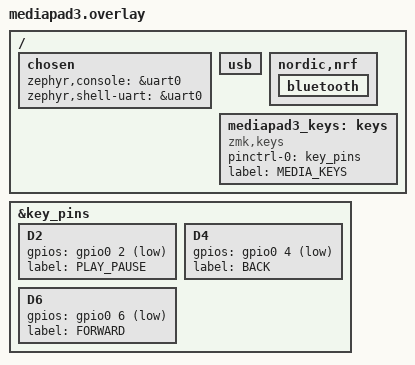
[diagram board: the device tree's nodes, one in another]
/ {
    chosen {
        zephyr,console = &uart0;
        zephyr,shell-uart = &uart0;
    };

    usb {
        status = "okay";
        #address-cells = <1>;
        #size-cells = <0>;
    };

    nordic,nrf {
        bluetooth {
            status = "okay";
        };
    };
};

/ {
    mediapad3_keys: keys {
        compatible = "zmk,keys";
        pinctrl-0 = <&key_pins>;
        pinctrl-names = "default";
        label = "MEDIA_KEYS";
    };
};

&key_pins {
    D2 {
        gpios = <&gpio0 2 GPIO_ACTIVE_LOW>;
        label = "PLAY_PAUSE";
    };
    D4 {
        gpios = <&gpio0 4 GPIO_ACTIVE_LOW>;
        label = "BACK";
    };
    D6 {
        gpios = <&gpio0 6 GPIO_ACTIVE_LOW>;
        label = "FORWARD";
    };
};
